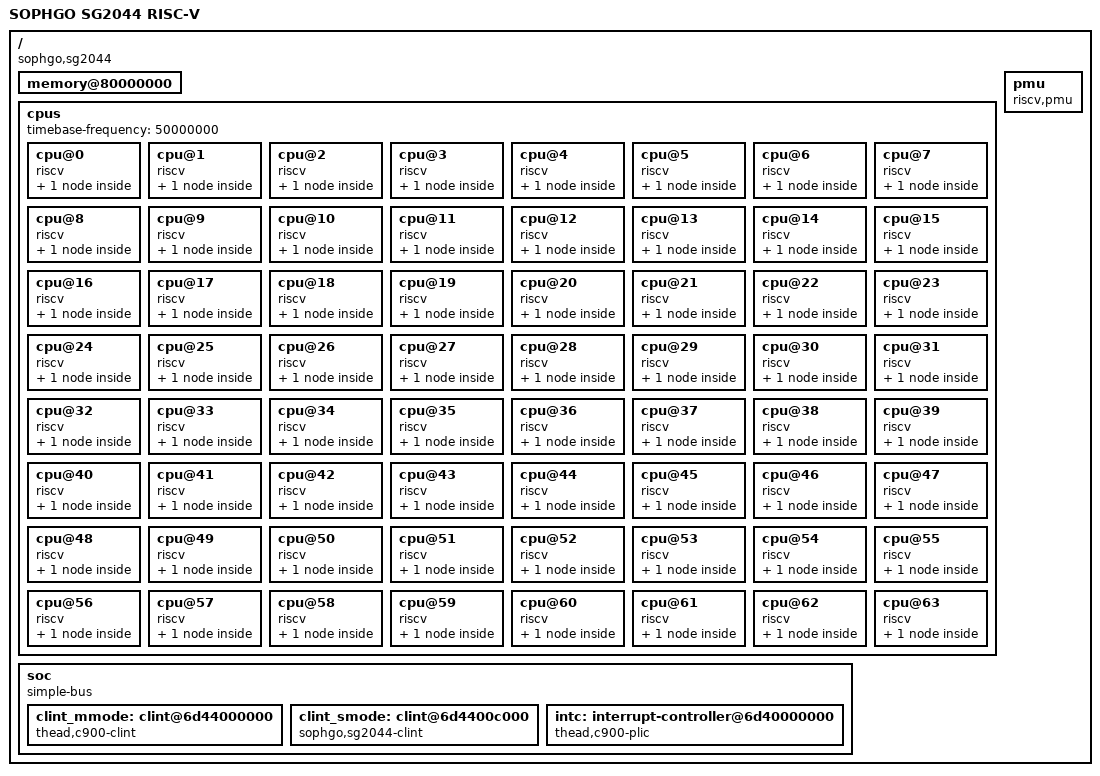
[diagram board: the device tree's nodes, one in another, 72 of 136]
// SPDX-License-Identifier: (GPL-2.0 OR MIT)
/*
 * Copyright (C) 2022 Sophgo Technology Inc. All rights reserved.
 */

/ {
	model = "SOPHGO SG2044 RISC-V";
	compatible = "sophgo,sg2044";
	#address-cells = <2>;
	#size-cells = <2>;
	dma-noncoherent;

	memory@80000000 {
		device_type = "memory";
		reg = <0x00000000 0x80000000 0x00000010 0x00000000>;
	};

	cpus {
		#address-cells = <1>;
		#size-cells = <0>;
		timebase-frequency = <50000000>;
		cpu@0 {
			device_type = "cpu";
			reg = <0>;
			status = "okay";
			compatible = "riscv";
			riscv,isa = "rv64imafdcv_zicbom_zicbop_zicboz_zicond1p0_zihintntl0p2_zihintpause_zawrs_zfa0p1_zfbfmin0p8_zfh_zca_zcb_zcd_zba_zbb_zbc_zbs_zvfbfmin0p8_zvfbfwma0p8_zvfh0p1_sscofpmf_sstc_svinval_svnapot_svpbmt";
			riscv,cbom-block-size = <64>;
			riscv,cboz-block-size = <64>;
			mmu-type = "riscv,sv48";
			cpu0_intc: interrupt-controller {
				#interrupt-cells = <1>;
				compatible = "riscv,cpu-intc";
				interrupt-controller;
			};
		};
		cpu@1 {
			device_type = "cpu";
			reg = <1>;
			status = "okay";
			compatible = "riscv";
			riscv,isa = "rv64imafdcv_zicbom_zicbop_zicboz_zicond1p0_zihintntl0p2_zihintpause_zawrs_zfa0p1_zfbfmin0p8_zfh_zca_zcb_zcd_zba_zbb_zbc_zbs_zvfbfmin0p8_zvfbfwma0p8_zvfh0p1_sscofpmf_sstc_svinval_svnapot_svpbmt";
			riscv,cbom-block-size = <64>;
			riscv,cboz-block-size = <64>;
			mmu-type = "riscv,sv48";
			cpu1_intc: interrupt-controller {
				#interrupt-cells = <1>;
				compatible = "riscv,cpu-intc";
				interrupt-controller;
			};
		};
		cpu@2 {
			device_type = "cpu";
			reg = <2>;
			status = "okay";
			compatible = "riscv";
			riscv,isa = "rv64imafdcv_zicbom_zicbop_zicboz_zicond1p0_zihintntl0p2_zihintpause_zawrs_zfa0p1_zfbfmin0p8_zfh_zca_zcb_zcd_zba_zbb_zbc_zbs_zvfbfmin0p8_zvfbfwma0p8_zvfh0p1_sscofpmf_sstc_svinval_svnapot_svpbmt";
			riscv,cbom-block-size = <64>;
			riscv,cboz-block-size = <64>;
			mmu-type = "riscv,sv48";
			cpu2_intc: interrupt-controller {
				#interrupt-cells = <1>;
				compatible = "riscv,cpu-intc";
				interrupt-controller;
			};
		};
		cpu@3 {
			device_type = "cpu";
			reg = <3>;
			status = "okay";
			compatible = "riscv";
			riscv,isa = "rv64imafdcv_zicbom_zicbop_zicboz_zicond1p0_zihintntl0p2_zihintpause_zawrs_zfa0p1_zfbfmin0p8_zfh_zca_zcb_zcd_zba_zbb_zbc_zbs_zvfbfmin0p8_zvfbfwma0p8_zvfh0p1_sscofpmf_sstc_svinval_svnapot_svpbmt";
			riscv,cbom-block-size = <64>;
			riscv,cboz-block-size = <64>;
			mmu-type = "riscv,sv48";
			cpu3_intc: interrupt-controller {
				#interrupt-cells = <1>;
				compatible = "riscv,cpu-intc";
				interrupt-controller;
			};
		};
		cpu@4 {
			device_type = "cpu";
			reg = <4>;
			status = "okay";
			compatible = "riscv";
			riscv,isa = "rv64imafdcv_zicbom_zicbop_zicboz_zicond1p0_zihintntl0p2_zihintpause_zawrs_zfa0p1_zfbfmin0p8_zfh_zca_zcb_zcd_zba_zbb_zbc_zbs_zvfbfmin0p8_zvfbfwma0p8_zvfh0p1_sscofpmf_sstc_svinval_svnapot_svpbmt";
			riscv,cbom-block-size = <64>;
			riscv,cboz-block-size = <64>;
			mmu-type = "riscv,sv48";
			cpu4_intc: interrupt-controller {
				#interrupt-cells = <1>;
				compatible = "riscv,cpu-intc";
				interrupt-controller;
			};
		};
		cpu@5 {
			device_type = "cpu";
			reg = <5>;
			status = "okay";
			compatible = "riscv";
			riscv,isa = "rv64imafdcv_zicbom_zicbop_zicboz_zicond1p0_zihintntl0p2_zihintpause_zawrs_zfa0p1_zfbfmin0p8_zfh_zca_zcb_zcd_zba_zbb_zbc_zbs_zvfbfmin0p8_zvfbfwma0p8_zvfh0p1_sscofpmf_sstc_svinval_svnapot_svpbmt";
			riscv,cbom-block-size = <64>;
			riscv,cboz-block-size = <64>;
			mmu-type = "riscv,sv48";
			cpu5_intc: interrupt-controller {
				#interrupt-cells = <1>;
				compatible = "riscv,cpu-intc";
				interrupt-controller;
			};
		};
		cpu@6 {
			device_type = "cpu";
			reg = <6>;
			status = "okay";
			compatible = "riscv";
			riscv,isa = "rv64imafdcv_zicbom_zicbop_zicboz_zicond1p0_zihintntl0p2_zihintpause_zawrs_zfa0p1_zfbfmin0p8_zfh_zca_zcb_zcd_zba_zbb_zbc_zbs_zvfbfmin0p8_zvfbfwma0p8_zvfh0p1_sscofpmf_sstc_svinval_svnapot_svpbmt";
			riscv,cbom-block-size = <64>;
			riscv,cboz-block-size = <64>;
			mmu-type = "riscv,sv48";
			cpu6_intc: interrupt-controller {
				#interrupt-cells = <1>;
				compatible = "riscv,cpu-intc";
				interrupt-controller;
			};
		};
		cpu@7 {
			device_type = "cpu";
			reg = <7>;
			status = "okay";
			compatible = "riscv";
			riscv,isa = "rv64imafdcv_zicbom_zicbop_zicboz_zicond1p0_zihintntl0p2_zihintpause_zawrs_zfa0p1_zfbfmin0p8_zfh_zca_zcb_zcd_zba_zbb_zbc_zbs_zvfbfmin0p8_zvfbfwma0p8_zvfh0p1_sscofpmf_sstc_svinval_svnapot_svpbmt";
			riscv,cbom-block-size = <64>;
			riscv,cboz-block-size = <64>;
			mmu-type = "riscv,sv48";
			cpu7_intc: interrupt-controller {
				#interrupt-cells = <1>;
				compatible = "riscv,cpu-intc";
				interrupt-controller;
			};
		};
		cpu@8 {
			device_type = "cpu";
			reg = <8>;
			status = "okay";
			compatible = "riscv";
			riscv,isa = "rv64imafdcv_zicbom_zicbop_zicboz_zicond1p0_zihintntl0p2_zihintpause_zawrs_zfa0p1_zfbfmin0p8_zfh_zca_zcb_zcd_zba_zbb_zbc_zbs_zvfbfmin0p8_zvfbfwma0p8_zvfh0p1_sscofpmf_sstc_svinval_svnapot_svpbmt";
			riscv,cbom-block-size = <64>;
			riscv,cboz-block-size = <64>;
			mmu-type = "riscv,sv48";
			cpu8_intc: interrupt-controller {
				#interrupt-cells = <1>;
				compatible = "riscv,cpu-intc";
				interrupt-controller;
			};
		};
		cpu@9 {
			device_type = "cpu";
			reg = <9>;
			status = "okay";
			compatible = "riscv";
			riscv,isa = "rv64imafdcv_zicbom_zicbop_zicboz_zicond1p0_zihintntl0p2_zihintpause_zawrs_zfa0p1_zfbfmin0p8_zfh_zca_zcb_zcd_zba_zbb_zbc_zbs_zvfbfmin0p8_zvfbfwma0p8_zvfh0p1_sscofpmf_sstc_svinval_svnapot_svpbmt";
			riscv,cbom-block-size = <64>;
			riscv,cboz-block-size = <64>;
			mmu-type = "riscv,sv48";
			cpu9_intc: interrupt-controller {
				#interrupt-cells = <1>;
				compatible = "riscv,cpu-intc";
				interrupt-controller;
			};
		};
		cpu@10 {
			device_type = "cpu";
			reg = <10>;
			status = "okay";
			compatible = "riscv";
			riscv,isa = "rv64imafdcv_zicbom_zicbop_zicboz_zicond1p0_zihintntl0p2_zihintpause_zawrs_zfa0p1_zfbfmin0p8_zfh_zca_zcb_zcd_zba_zbb_zbc_zbs_zvfbfmin0p8_zvfbfwma0p8_zvfh0p1_sscofpmf_sstc_svinval_svnapot_svpbmt";
			riscv,cbom-block-size = <64>;
			riscv,cboz-block-size = <64>;
			mmu-type = "riscv,sv48";
			cpu10_intc: interrupt-controller {
				#interrupt-cells = <1>;
				compatible = "riscv,cpu-intc";
				interrupt-controller;
			};
		};
		cpu@11 {
			device_type = "cpu";
			reg = <11>;
			status = "okay";
			compatible = "riscv";
			riscv,isa = "rv64imafdcv_zicbom_zicbop_zicboz_zicond1p0_zihintntl0p2_zihintpause_zawrs_zfa0p1_zfbfmin0p8_zfh_zca_zcb_zcd_zba_zbb_zbc_zbs_zvfbfmin0p8_zvfbfwma0p8_zvfh0p1_sscofpmf_sstc_svinval_svnapot_svpbmt";
			riscv,cbom-block-size = <64>;
			riscv,cboz-block-size = <64>;
			mmu-type = "riscv,sv48";
			cpu11_intc: interrupt-controller {
				#interrupt-cells = <1>;
				compatible = "riscv,cpu-intc";
				interrupt-controller;
			};
		};
		cpu@12 {
			device_type = "cpu";
			reg = <12>;
			status = "okay";
			compatible = "riscv";
			riscv,isa = "rv64imafdcv_zicbom_zicbop_zicboz_zicond1p0_zihintntl0p2_zihintpause_zawrs_zfa0p1_zfbfmin0p8_zfh_zca_zcb_zcd_zba_zbb_zbc_zbs_zvfbfmin0p8_zvfbfwma0p8_zvfh0p1_sscofpmf_sstc_svinval_svnapot_svpbmt";
			riscv,cbom-block-size = <64>;
			riscv,cboz-block-size = <64>;
			mmu-type = "riscv,sv48";
			cpu12_intc: interrupt-controller {
				#interrupt-cells = <1>;
				compatible = "riscv,cpu-intc";
				interrupt-controller;
			};
		};
		cpu@13 {
			device_type = "cpu";
			reg = <13>;
			status = "okay";
			compatible = "riscv";
			riscv,isa = "rv64imafdcv_zicbom_zicbop_zicboz_zicond1p0_zihintntl0p2_zihintpause_zawrs_zfa0p1_zfbfmin0p8_zfh_zca_zcb_zcd_zba_zbb_zbc_zbs_zvfbfmin0p8_zvfbfwma0p8_zvfh0p1_sscofpmf_sstc_svinval_svnapot_svpbmt";
			riscv,cbom-block-size = <64>;
			riscv,cboz-block-size = <64>;
			mmu-type = "riscv,sv48";
			cpu13_intc: interrupt-controller {
				#interrupt-cells = <1>;
				compatible = "riscv,cpu-intc";
				interrupt-controller;
			};
		};
		cpu@14 {
			device_type = "cpu";
			reg = <14>;
			status = "okay";
			compatible = "riscv";
			riscv,isa = "rv64imafdcv_zicbom_zicbop_zicboz_zicond1p0_zihintntl0p2_zihintpause_zawrs_zfa0p1_zfbfmin0p8_zfh_zca_zcb_zcd_zba_zbb_zbc_zbs_zvfbfmin0p8_zvfbfwma0p8_zvfh0p1_sscofpmf_sstc_svinval_svnapot_svpbmt";
			riscv,cbom-block-size = <64>;
			riscv,cboz-block-size = <64>;
			mmu-type = "riscv,sv48";
			cpu14_intc: interrupt-controller {
				#interrupt-cells = <1>;
				compatible = "riscv,cpu-intc";
				interrupt-controller;
			};
		};
		cpu@15 {
			device_type = "cpu";
			reg = <15>;
			status = "okay";
			compatible = "riscv";
			riscv,isa = "rv64imafdcv_zicbom_zicbop_zicboz_zicond1p0_zihintntl0p2_zihintpause_zawrs_zfa0p1_zfbfmin0p8_zfh_zca_zcb_zcd_zba_zbb_zbc_zbs_zvfbfmin0p8_zvfbfwma0p8_zvfh0p1_sscofpmf_sstc_svinval_svnapot_svpbmt";
			riscv,cbom-block-size = <64>;
			riscv,cboz-block-size = <64>;
			mmu-type = "riscv,sv48";
			cpu15_intc: interrupt-controller {
				#interrupt-cells = <1>;
				compatible = "riscv,cpu-intc";
				interrupt-controller;
			};
		};
		cpu@16 {
			device_type = "cpu";
			reg = <16>;
			status = "okay";
			compatible = "riscv";
			riscv,isa = "rv64imafdcv_zicbom_zicbop_zicboz_zicond1p0_zihintntl0p2_zihintpause_zawrs_zfa0p1_zfbfmin0p8_zfh_zca_zcb_zcd_zba_zbb_zbc_zbs_zvfbfmin0p8_zvfbfwma0p8_zvfh0p1_sscofpmf_sstc_svinval_svnapot_svpbmt";
			riscv,cbom-block-size = <64>;
			riscv,cboz-block-size = <64>;
			mmu-type = "riscv,sv48";
			cpu16_intc: interrupt-controller {
				#interrupt-cells = <1>;
				compatible = "riscv,cpu-intc";
				interrupt-controller;
			};
		};
		cpu@17 {
			device_type = "cpu";
			reg = <17>;
			status = "okay";
			compatible = "riscv";
			riscv,isa = "rv64imafdcv_zicbom_zicbop_zicboz_zicond1p0_zihintntl0p2_zihintpause_zawrs_zfa0p1_zfbfmin0p8_zfh_zca_zcb_zcd_zba_zbb_zbc_zbs_zvfbfmin0p8_zvfbfwma0p8_zvfh0p1_sscofpmf_sstc_svinval_svnapot_svpbmt";
			riscv,cbom-block-size = <64>;
			riscv,cboz-block-size = <64>;
			mmu-type = "riscv,sv48";
			cpu17_intc: interrupt-controller {
				#interrupt-cells = <1>;
				compatible = "riscv,cpu-intc";
				interrupt-controller;
			};
		};
		cpu@18 {
			device_type = "cpu";
			reg = <18>;
			status = "okay";
			compatible = "riscv";
			riscv,isa = "rv64imafdcv_zicbom_zicbop_zicboz_zicond1p0_zihintntl0p2_zihintpause_zawrs_zfa0p1_zfbfmin0p8_zfh_zca_zcb_zcd_zba_zbb_zbc_zbs_zvfbfmin0p8_zvfbfwma0p8_zvfh0p1_sscofpmf_sstc_svinval_svnapot_svpbmt";
			riscv,cbom-block-size = <64>;
			riscv,cboz-block-size = <64>;
			mmu-type = "riscv,sv48";
			cpu18_intc: interrupt-controller {
				#interrupt-cells = <1>;
				compatible = "riscv,cpu-intc";
				interrupt-controller;
			};
		};
		cpu@19 {
			device_type = "cpu";
			reg = <19>;
			status = "okay";
			compatible = "riscv";
			riscv,isa = "rv64imafdcv_zicbom_zicbop_zicboz_zicond1p0_zihintntl0p2_zihintpause_zawrs_zfa0p1_zfbfmin0p8_zfh_zca_zcb_zcd_zba_zbb_zbc_zbs_zvfbfmin0p8_zvfbfwma0p8_zvfh0p1_sscofpmf_sstc_svinval_svnapot_svpbmt";
			riscv,cbom-block-size = <64>;
			riscv,cboz-block-size = <64>;
			mmu-type = "riscv,sv48";
			cpu19_intc: interrupt-controller {
				#interrupt-cells = <1>;
				compatible = "riscv,cpu-intc";
				interrupt-controller;
			};
		};
		cpu@20 {
			device_type = "cpu";
			reg = <20>;
			status = "okay";
			compatible = "riscv";
			riscv,isa = "rv64imafdcv_zicbom_zicbop_zicboz_zicond1p0_zihintntl0p2_zihintpause_zawrs_zfa0p1_zfbfmin0p8_zfh_zca_zcb_zcd_zba_zbb_zbc_zbs_zvfbfmin0p8_zvfbfwma0p8_zvfh0p1_sscofpmf_sstc_svinval_svnapot_svpbmt";
			riscv,cbom-block-size = <64>;
			riscv,cboz-block-size = <64>;
			mmu-type = "riscv,sv48";
			cpu20_intc: interrupt-controller {
				#interrupt-cells = <1>;
				compatible = "riscv,cpu-intc";
				interrupt-controller;
			};
		};
		cpu@21 {
			device_type = "cpu";
			reg = <21>;
			status = "okay";
			compatible = "riscv";
			riscv,isa = "rv64imafdcv_zicbom_zicbop_zicboz_zicond1p0_zihintntl0p2_zihintpause_zawrs_zfa0p1_zfbfmin0p8_zfh_zca_zcb_zcd_zba_zbb_zbc_zbs_zvfbfmin0p8_zvfbfwma0p8_zvfh0p1_sscofpmf_sstc_svinval_svnapot_svpbmt";
			riscv,cbom-block-size = <64>;
			riscv,cboz-block-size = <64>;
			mmu-type = "riscv,sv48";
			cpu21_intc: interrupt-controller {
				#interrupt-cells = <1>;
				compatible = "riscv,cpu-intc";
				interrupt-controller;
			};
		};
		cpu@22 {
			device_type = "cpu";
			reg = <22>;
			status = "okay";
			compatible = "riscv";
			riscv,isa = "rv64imafdcv_zicbom_zicbop_zicboz_zicond1p0_zihintntl0p2_zihintpause_zawrs_zfa0p1_zfbfmin0p8_zfh_zca_zcb_zcd_zba_zbb_zbc_zbs_zvfbfmin0p8_zvfbfwma0p8_zvfh0p1_sscofpmf_sstc_svinval_svnapot_svpbmt";
			riscv,cbom-block-size = <64>;
			riscv,cboz-block-size = <64>;
			mmu-type = "riscv,sv48";
			cpu22_intc: interrupt-controller {
				#interrupt-cells = <1>;
				compatible = "riscv,cpu-intc";
				interrupt-controller;
			};
		};
		cpu@23 {
			device_type = "cpu";
			reg = <23>;
			status = "okay";
			compatible = "riscv";
			riscv,isa = "rv64imafdcv_zicbom_zicbop_zicboz_zicond1p0_zihintntl0p2_zihintpause_zawrs_zfa0p1_zfbfmin0p8_zfh_zca_zcb_zcd_zba_zbb_zbc_zbs_zvfbfmin0p8_zvfbfwma0p8_zvfh0p1_sscofpmf_sstc_svinval_svnapot_svpbmt";
			riscv,cbom-block-size = <64>;
			riscv,cboz-block-size = <64>;
			mmu-type = "riscv,sv48";
			cpu23_intc: interrupt-controller {
				#interrupt-cells = <1>;
				compatible = "riscv,cpu-intc";
				interrupt-controller;
			};
		};
		cpu@24 {
			device_type = "cpu";
			reg = <24>;
			status = "okay";
			compatible = "riscv";
			riscv,isa = "rv64imafdcv_zicbom_zicbop_zicboz_zicond1p0_zihintntl0p2_zihintpause_zawrs_zfa0p1_zfbfmin0p8_zfh_zca_zcb_zcd_zba_zbb_zbc_zbs_zvfbfmin0p8_zvfbfwma0p8_zvfh0p1_sscofpmf_sstc_svinval_svnapot_svpbmt";
			riscv,cbom-block-size = <64>;
			riscv,cboz-block-size = <64>;
			mmu-type = "riscv,sv48";
			cpu24_intc: interrupt-controller {
				#interrupt-cells = <1>;
				compatible = "riscv,cpu-intc";
				interrupt-controller;
			};
		};
		cpu@25 {
			device_type = "cpu";
			reg = <25>;
			status = "okay";
			compatible = "riscv";
			riscv,isa = "rv64imafdcv_zicbom_zicbop_zicboz_zicond1p0_zihintntl0p2_zihintpause_zawrs_zfa0p1_zfbfmin0p8_zfh_zca_zcb_zcd_zba_zbb_zbc_zbs_zvfbfmin0p8_zvfbfwma0p8_zvfh0p1_sscofpmf_sstc_svinval_svnapot_svpbmt";
			riscv,cbom-block-size = <64>;
			riscv,cboz-block-size = <64>;
			mmu-type = "riscv,sv48";
			cpu25_intc: interrupt-controller {
				#interrupt-cells = <1>;
				compatible = "riscv,cpu-intc";
				interrupt-controller;
			};
		};
		cpu@26 {
			device_type = "cpu";
			reg = <26>;
			status = "okay";
			compatible = "riscv";
			riscv,isa = "rv64imafdcv_zicbom_zicbop_zicboz_zicond1p0_zihintntl0p2_zihintpause_zawrs_zfa0p1_zfbfmin0p8_zfh_zca_zcb_zcd_zba_zbb_zbc_zbs_zvfbfmin0p8_zvfbfwma0p8_zvfh0p1_sscofpmf_sstc_svinval_svnapot_svpbmt";
			riscv,cbom-block-size = <64>;
			riscv,cboz-block-size = <64>;
			mmu-type = "riscv,sv48";
			cpu26_intc: interrupt-controller {
				#interrupt-cells = <1>;
				compatible = "riscv,cpu-intc";
				interrupt-controller;
			};
		};
		cpu@27 {
			device_type = "cpu";
			reg = <27>;
			status = "okay";
			compatible = "riscv";
			riscv,isa = "rv64imafdcv_zicbom_zicbop_zicboz_zicond1p0_zihintntl0p2_zihintpause_zawrs_zfa0p1_zfbfmin0p8_zfh_zca_zcb_zcd_zba_zbb_zbc_zbs_zvfbfmin0p8_zvfbfwma0p8_zvfh0p1_sscofpmf_sstc_svinval_svnapot_svpbmt";
			riscv,cbom-block-size = <64>;
			riscv,cboz-block-size = <64>;
			mmu-type = "riscv,sv48";
			cpu27_intc: interrupt-controller {
				#interrupt-cells = <1>;
				compatible = "riscv,cpu-intc";
				interrupt-controller;
			};
		};
		cpu@28 {
			device_type = "cpu";
			reg = <28>;
			status = "okay";
			compatible = "riscv";
			riscv,isa = "rv64imafdcv_zicbom_zicbop_zicboz_zicond1p0_zihintntl0p2_zihintpause_zawrs_zfa0p1_zfbfmin0p8_zfh_zca_zcb_zcd_zba_zbb_zbc_zbs_zvfbfmin0p8_zvfbfwma0p8_zvfh0p1_sscofpmf_sstc_svinval_svnapot_svpbmt";
			riscv,cbom-block-size = <64>;
			riscv,cboz-block-size = <64>;
			mmu-type = "riscv,sv48";
			cpu28_intc: interrupt-controller {
				#interrupt-cells = <1>;
				compatible = "riscv,cpu-intc";
				interrupt-controller;
			};
		};
		cpu@29 {
			device_type = "cpu";
			reg = <29>;
			status = "okay";
			compatible = "riscv";
			riscv,isa = "rv64imafdcv_zicbom_zicbop_zicboz_zicond1p0_zihintntl0p2_zihintpause_zawrs_zfa0p1_zfbfmin0p8_zfh_zca_zcb_zcd_zba_zbb_zbc_zbs_zvfbfmin0p8_zvfbfwma0p8_zvfh0p1_sscofpmf_sstc_svinval_svnapot_svpbmt";
			riscv,cbom-block-size = <64>;
			riscv,cboz-block-size = <64>;
			mmu-type = "riscv,sv48";
			cpu29_intc: interrupt-controller {
				#interrupt-cells = <1>;
				compatible = "riscv,cpu-intc";
				interrupt-controller;
			};
		};
		cpu@30 {
			device_type = "cpu";
			reg = <30>;
			status = "okay";
			compatible = "riscv";
			riscv,isa = "rv64imafdcv_zicbom_zicbop_zicboz_zicond1p0_zihintntl0p2_zihintpause_zawrs_zfa0p1_zfbfmin0p8_zfh_zca_zcb_zcd_zba_zbb_zbc_zbs_zvfbfmin0p8_zvfbfwma0p8_zvfh0p1_sscofpmf_sstc_svinval_svnapot_svpbmt";
			riscv,cbom-block-size = <64>;
			riscv,cboz-block-size = <64>;
			mmu-type = "riscv,sv48";
			cpu30_intc: interrupt-controller {
				#interrupt-cells = <1>;
				compatible = "riscv,cpu-intc";
				interrupt-controller;
			};
		};
		cpu@31 {
			device_type = "cpu";
			reg = <31>;
			status = "okay";
			compatible = "riscv";
			riscv,isa = "rv64imafdcv_zicbom_zicbop_zicboz_zicond1p0_zihintntl0p2_zihintpause_zawrs_zfa0p1_zfbfmin0p8_zfh_zca_zcb_zcd_zba_zbb_zbc_zbs_zvfbfmin0p8_zvfbfwma0p8_zvfh0p1_sscofpmf_sstc_svinval_svnapot_svpbmt";
			riscv,cbom-block-size = <64>;
			riscv,cboz-block-size = <64>;
			mmu-type = "riscv,sv48";
			cpu31_intc: interrupt-controller {
				#interrupt-cells = <1>;
				compatible = "riscv,cpu-intc";
				interrupt-controller;
			};
		};
		cpu@32 {
			device_type = "cpu";
			reg = <32>;
			status = "okay";
			compatible = "riscv";
			riscv,isa = "rv64imafdcv_zicbom_zicbop_zicboz_zicond1p0_zihintntl0p2_zihintpause_zawrs_zfa0p1_zfbfmin0p8_zfh_zca_zcb_zcd_zba_zbb_zbc_zbs_zvfbfmin0p8_zvfbfwma0p8_zvfh0p1_sscofpmf_sstc_svinval_svnapot_svpbmt";
			riscv,cbom-block-size = <64>;
			riscv,cboz-block-size = <64>;
			mmu-type = "riscv,sv48";
			cpu32_intc: interrupt-controller {
				#interrupt-cells = <1>;
				compatible = "riscv,cpu-intc";
				interrupt-controller;
			};
		};
		cpu@33 {
			device_type = "cpu";
			reg = <33>;
			status = "okay";
			compatible = "riscv";
			riscv,isa = "rv64imafdcv_zicbom_zicbop_zicboz_zicond1p0_zihintntl0p2_zihintpause_zawrs_zfa0p1_zfbfmin0p8_zfh_zca_zcb_zcd_zba_zbb_zbc_zbs_zvfbfmin0p8_zvfbfwma0p8_zvfh0p1_sscofpmf_sstc_svinval_svnapot_svpbmt";
			riscv,cbom-block-size = <64>;
			riscv,cboz-block-size = <64>;
			mmu-type = "riscv,sv48";
			cpu33_intc: interrupt-controller {
				#interrupt-cells = <1>;
				compatible = "riscv,cpu-intc";
				interrupt-controller;
			};
		};
		cpu@34 {
			device_type = "cpu";
			reg = <34>;
			status = "okay";
			compatible = "riscv";
			riscv,isa = "rv64imafdcv_zicbom_zicbop_zicboz_zicond1p0_zihintntl0p2_zihintpause_zawrs_zfa0p1_zfbfmin0p8_zfh_zca_zcb_zcd_zba_zbb_zbc_zbs_zvfbfmin0p8_zvfbfwma0p8_zvfh0p1_sscofpmf_sstc_svinval_svnapot_svpbmt";
			riscv,cbom-block-size = <64>;
			riscv,cboz-block-size = <64>;
			mmu-type = "riscv,sv48";
			cpu34_intc: interrupt-controller {
				#interrupt-cells = <1>;
				compatible = "riscv,cpu-intc";
				interrupt-controller;
			};
		};
		cpu@35 {
			device_type = "cpu";
			reg = <35>;
			status = "okay";
			compatible = "riscv";
			riscv,isa = "rv64imafdcv_zicbom_zicbop_zicboz_zicond1p0_zihintntl0p2_zihintpause_zawrs_zfa0p1_zfbfmin0p8_zfh_zca_zcb_zcd_zba_zbb_zbc_zbs_zvfbfmin0p8_zvfbfwma0p8_zvfh0p1_sscofpmf_sstc_svinval_svnapot_svpbmt";
			riscv,cbom-block-size = <64>;
			riscv,cboz-block-size = <64>;
			mmu-type = "riscv,sv48";
			cpu35_intc: interrupt-controller {
				#interrupt-cells = <1>;
				compatible = "riscv,cpu-intc";
				interrupt-controller;
			};
		};
		cpu@36 {
			device_type = "cpu";
			reg = <36>;
			status = "okay";
			compatible = "riscv";
			riscv,isa = "rv64imafdcv_zicbom_zicbop_zicboz_zicond1p0_zihintntl0p2_zihintpause_zawrs_zfa0p1_zfbfmin0p8_zfh_zca_zcb_zcd_zba_zbb_zbc_zbs_zvfbfmin0p8_zvfbfwma0p8_zvfh0p1_sscofpmf_sstc_svinval_svnapot_svpbmt";
			riscv,cbom-block-size = <64>;
			riscv,cboz-block-size = <64>;
			mmu-type = "riscv,sv48";
			cpu36_intc: interrupt-controller {
				#interrupt-cells = <1>;
				compatible = "riscv,cpu-intc";
				interrupt-controller;
			};
		};
		cpu@37 {
			device_type = "cpu";
			reg = <37>;
			status = "okay";
			compatible = "riscv";
			riscv,isa = "rv64imafdcv_zicbom_zicbop_zicboz_zicond1p0_zihintntl0p2_zihintpause_zawrs_zfa0p1_zfbfmin0p8_zfh_zca_zcb_zcd_zba_zbb_zbc_zbs_zvfbfmin0p8_zvfbfwma0p8_zvfh0p1_sscofpmf_sstc_svinval_svnapot_svpbmt";
			riscv,cbom-block-size = <64>;
			riscv,cboz-block-size = <64>;
			mmu-type = "riscv,sv48";
			cpu37_intc: interrupt-controller {
				#interrupt-cells = <1>;
				compatible = "riscv,cpu-intc";
				interrupt-controller;
			};
		};
		cpu@38 {
			device_type = "cpu";
			reg = <38>;
			status = "okay";
			compatible = "riscv";
			riscv,isa = "rv64imafdcv_zicbom_zicbop_zicboz_zicond1p0_zihintntl0p2_zihintpause_zawrs_zfa0p1_zfbfmin0p8_zfh_zca_zcb_zcd_zba_zbb_zbc_zbs_zvfbfmin0p8_zvfbfwma0p8_zvfh0p1_sscofpmf_sstc_svinval_svnapot_svpbmt";
			riscv,cbom-block-size = <64>;
			riscv,cboz-block-size = <64>;
			mmu-type = "riscv,sv48";
			cpu38_intc: interrupt-controller {
				#interrupt-cells = <1>;
				compatible = "riscv,cpu-intc";
				interrupt-controller;
			};
		};
		cpu@39 {
			device_type = "cpu";
			reg = <39>;
			status = "okay";
			compatible = "riscv";
			riscv,isa = "rv64imafdcv_zicbom_zicbop_zicboz_zicond1p0_zihintntl0p2_zihintpause_zawrs_zfa0p1_zfbfmin0p8_zfh_zca_zcb_zcd_zba_zbb_zbc_zbs_zvfbfmin0p8_zvfbfwma0p8_zvfh0p1_sscofpmf_sstc_svinval_svnapot_svpbmt";
			riscv,cbom-block-size = <64>;
			riscv,cboz-block-size = <64>;
			mmu-type = "riscv,sv48";
			cpu39_intc: interrupt-controller {
				#interrupt-cells = <1>;
				compatible = "riscv,cpu-intc";
				interrupt-controller;
			};
		};
		cpu@40 {
			device_type = "cpu";
			reg = <40>;
			status = "okay";
			compatible = "riscv";
			riscv,isa = "rv64imafdcv_zicbom_zicbop_zicboz_zicond1p0_zihintntl0p2_zihintpause_zawrs_zfa0p1_zfbfmin0p8_zfh_zca_zcb_zcd_zba_zbb_zbc_zbs_zvfbfmin0p8_zvfbfwma0p8_zvfh0p1_sscofpmf_sstc_svinval_svnapot_svpbmt";
			riscv,cbom-block-size = <64>;
			riscv,cboz-block-size = <64>;
			mmu-type = "riscv,sv48";
			cpu40_intc: interrupt-controller {
				#interrupt-cells = <1>;
				compatible = "riscv,cpu-intc";
				interrupt-controller;
			};
		};
		cpu@41 {
			device_type = "cpu";
			reg = <41>;
			status = "okay";
			compatible = "riscv";
			riscv,isa = "rv64imafdcv_zicbom_zicbop_zicboz_zicond1p0_zihintntl0p2_zihintpause_zawrs_zfa0p1_zfbfmin0p8_zfh_zca_zcb_zcd_zba_zbb_zbc_zbs_zvfbfmin0p8_zvfbfwma0p8_zvfh0p1_sscofpmf_sstc_svinval_svnapot_svpbmt";
			riscv,cbom-block-size = <64>;
			riscv,cboz-block-size = <64>;
			mmu-type = "riscv,sv48";
			cpu41_intc: interrupt-controller {
				#interrupt-cells = <1>;
				compatible = "riscv,cpu-intc";
				interrupt-controller;
			};
		};
		cpu@42 {
			device_type = "cpu";
			reg = <42>;
			status = "okay";
			compatible = "riscv";
			riscv,isa = "rv64imafdcv_zicbom_zicbop_zicboz_zicond1p0_zihintntl0p2_zihintpause_zawrs_zfa0p1_zfbfmin0p8_zfh_zca_zcb_zcd_zba_zbb_zbc_zbs_zvfbfmin0p8_zvfbfwma0p8_zvfh0p1_sscofpmf_sstc_svinval_svnapot_svpbmt";
			riscv,cbom-block-size = <64>;
			riscv,cboz-block-size = <64>;
			mmu-type = "riscv,sv48";
			cpu42_intc: interrupt-controller {
				#interrupt-cells = <1>;
				compatible = "riscv,cpu-intc";
				interrupt-controller;
			};
		};
		cpu@43 {
			device_type = "cpu";
			reg = <43>;
			status = "okay";
			compatible = "riscv";
			riscv,isa = "rv64imafdcv_zicbom_zicbop_zicboz_zicond1p0_zihintntl0p2_zihintpause_zawrs_zfa0p1_zfbfmin0p8_zfh_zca_zcb_zcd_zba_zbb_zbc_zbs_zvfbfmin0p8_zvfbfwma0p8_zvfh0p1_sscofpmf_sstc_svinval_svnapot_svpbmt";
			riscv,cbom-block-size = <64>;
			riscv,cboz-block-size = <64>;
			mmu-type = "riscv,sv48";
			cpu43_intc: interrupt-controller {
				#interrupt-cells = <1>;
				compatible = "riscv,cpu-intc";
				interrupt-controller;
			};
		};
		cpu@44 {
			device_type = "cpu";
			reg = <44>;
			status = "okay";
			compatible = "riscv";
			riscv,isa = "rv64imafdcv_zicbom_zicbop_zicboz_zicond1p0_zihintntl0p2_zihintpause_zawrs_zfa0p1_zfbfmin0p8_zfh_zca_zcb_zcd_zba_zbb_zbc_zbs_zvfbfmin0p8_zvfbfwma0p8_zvfh0p1_sscofpmf_sstc_svinval_svnapot_svpbmt";
			riscv,cbom-block-size = <64>;
			riscv,cboz-block-size = <64>;
			mmu-type = "riscv,sv48";
			cpu44_intc: interrupt-controller {
				#interrupt-cells = <1>;
				compatible = "riscv,cpu-intc";
				interrupt-controller;
			};
		};
		cpu@45 {
			device_type = "cpu";
			reg = <45>;
			status = "okay";
			compatible = "riscv";
			riscv,isa = "rv64imafdcv_zicbom_zicbop_zicboz_zicond1p0_zihintntl0p2_zihintpause_zawrs_zfa0p1_zfbfmin0p8_zfh_zca_zcb_zcd_zba_zbb_zbc_zbs_zvfbfmin0p8_zvfbfwma0p8_zvfh0p1_sscofpmf_sstc_svinval_svnapot_svpbmt";
			riscv,cbom-block-size = <64>;
			riscv,cboz-block-size = <64>;
			mmu-type = "riscv,sv48";
			cpu45_intc: interrupt-controller {
				#interrupt-cells = <1>;
				compatible = "riscv,cpu-intc";
				interrupt-controller;
			};
		};
		cpu@46 {
			device_type = "cpu";
			reg = <46>;
			status = "okay";
			compatible = "riscv";
			riscv,isa = "rv64imafdcv_zicbom_zicbop_zicboz_zicond1p0_zihintntl0p2_zihintpause_zawrs_zfa0p1_zfbfmin0p8_zfh_zca_zcb_zcd_zba_zbb_zbc_zbs_zvfbfmin0p8_zvfbfwma0p8_zvfh0p1_sscofpmf_sstc_svinval_svnapot_svpbmt";
			riscv,cbom-block-size = <64>;
			riscv,cboz-block-size = <64>;
			mmu-type = "riscv,sv48";
			cpu46_intc: interrupt-controller {
				#interrupt-cells = <1>;
				compatible = "riscv,cpu-intc";
				interrupt-controller;
			};
		};
		cpu@47 {
			device_type = "cpu";
			reg = <47>;
			status = "okay";
			compatible = "riscv";
			riscv,isa = "rv64imafdcv_zicbom_zicbop_zicboz_zicond1p0_zihintntl0p2_zihintpause_zawrs_zfa0p1_zfbfmin0p8_zfh_zca_zcb_zcd_zba_zbb_zbc_zbs_zvfbfmin0p8_zvfbfwma0p8_zvfh0p1_sscofpmf_sstc_svinval_svnapot_svpbmt";
			riscv,cbom-block-size = <64>;
			riscv,cboz-block-size = <64>;
			mmu-type = "riscv,sv48";
			cpu47_intc: interrupt-controller {
				#interrupt-cells = <1>;
				compatible = "riscv,cpu-intc";
				interrupt-controller;
			};
		};
		cpu@48 {
			device_type = "cpu";
			reg = <48>;
			status = "okay";
			compatible = "riscv";
			riscv,isa = "rv64imafdcv_zicbom_zicbop_zicboz_zicond1p0_zihintntl0p2_zihintpause_zawrs_zfa0p1_zfbfmin0p8_zfh_zca_zcb_zcd_zba_zbb_zbc_zbs_zvfbfmin0p8_zvfbfwma0p8_zvfh0p1_sscofpmf_sstc_svinval_svnapot_svpbmt";
			riscv,cbom-block-size = <64>;
			riscv,cboz-block-size = <64>;
			mmu-type = "riscv,sv48";
			cpu48_intc: interrupt-controller {
				#interrupt-cells = <1>;
				compatible = "riscv,cpu-intc";
				interrupt-controller;
			};
		};
		cpu@49 {
			device_type = "cpu";
			reg = <49>;
			status = "okay";
			compatible = "riscv";
			riscv,isa = "rv64imafdcv_zicbom_zicbop_zicboz_zicond1p0_zihintntl0p2_zihintpause_zawrs_zfa0p1_zfbfmin0p8_zfh_zca_zcb_zcd_zba_zbb_zbc_zbs_zvfbfmin0p8_zvfbfwma0p8_zvfh0p1_sscofpmf_sstc_svinval_svnapot_svpbmt";
			riscv,cbom-block-size = <64>;
			riscv,cboz-block-size = <64>;
			mmu-type = "riscv,sv48";
			cpu49_intc: interrupt-controller {
				#interrupt-cells = <1>;
				compatible = "riscv,cpu-intc";
				interrupt-controller;
			};
		};
		cpu@50 {
			device_type = "cpu";
			reg = <50>;
			status = "okay";
			compatible = "riscv";
			riscv,isa = "rv64imafdcv_zicbom_zicbop_zicboz_zicond1p0_zihintntl0p2_zihintpause_zawrs_zfa0p1_zfbfmin0p8_zfh_zca_zcb_zcd_zba_zbb_zbc_zbs_zvfbfmin0p8_zvfbfwma0p8_zvfh0p1_sscofpmf_sstc_svinval_svnapot_svpbmt";
			riscv,cbom-block-size = <64>;
			riscv,cboz-block-size = <64>;
			mmu-type = "riscv,sv48";
			cpu50_intc: interrupt-controller {
				#interrupt-cells = <1>;
				compatible = "riscv,cpu-intc";
				interrupt-controller;
			};
		};
		cpu@51 {
			device_type = "cpu";
			reg = <51>;
			status = "okay";
			compatible = "riscv";
			riscv,isa = "rv64imafdcv_zicbom_zicbop_zicboz_zicond1p0_zihintntl0p2_zihintpause_zawrs_zfa0p1_zfbfmin0p8_zfh_zca_zcb_zcd_zba_zbb_zbc_zbs_zvfbfmin0p8_zvfbfwma0p8_zvfh0p1_sscofpmf_sstc_svinval_svnapot_svpbmt";
			riscv,cbom-block-size = <64>;
			riscv,cboz-block-size = <64>;
			mmu-type = "riscv,sv48";
			cpu51_intc: interrupt-controller {
				#interrupt-cells = <1>;
				compatible = "riscv,cpu-intc";
				interrupt-controller;
			};
		};
		cpu@52 {
			device_type = "cpu";
			reg = <52>;
			status = "okay";
			compatible = "riscv";
			riscv,isa = "rv64imafdcv_zicbom_zicbop_zicboz_zicond1p0_zihintntl0p2_zihintpause_zawrs_zfa0p1_zfbfmin0p8_zfh_zca_zcb_zcd_zba_zbb_zbc_zbs_zvfbfmin0p8_zvfbfwma0p8_zvfh0p1_sscofpmf_sstc_svinval_svnapot_svpbmt";
			riscv,cbom-block-size = <64>;
			riscv,cboz-block-size = <64>;
			mmu-type = "riscv,sv48";
			cpu52_intc: interrupt-controller {
				#interrupt-cells = <1>;
				compatible = "riscv,cpu-intc";
				interrupt-controller;
			};
		};
		cpu@53 {
			device_type = "cpu";
			reg = <53>;
			status = "okay";
			compatible = "riscv";
			riscv,isa = "rv64imafdcv_zicbom_zicbop_zicboz_zicond1p0_zihintntl0p2_zihintpause_zawrs_zfa0p1_zfbfmin0p8_zfh_zca_zcb_zcd_zba_zbb_zbc_zbs_zvfbfmin0p8_zvfbfwma0p8_zvfh0p1_sscofpmf_sstc_svinval_svnapot_svpbmt";
			riscv,cbom-block-size = <64>;
			riscv,cboz-block-size = <64>;
			mmu-type = "riscv,sv48";
			cpu53_intc: interrupt-controller {
				#interrupt-cells = <1>;
				compatible = "riscv,cpu-intc";
				interrupt-controller;
			};
		};
		cpu@54 {
			device_type = "cpu";
			reg = <54>;
			status = "okay";
			compatible = "riscv";
			riscv,isa = "rv64imafdcv_zicbom_zicbop_zicboz_zicond1p0_zihintntl0p2_zihintpause_zawrs_zfa0p1_zfbfmin0p8_zfh_zca_zcb_zcd_zba_zbb_zbc_zbs_zvfbfmin0p8_zvfbfwma0p8_zvfh0p1_sscofpmf_sstc_svinval_svnapot_svpbmt";
			riscv,cbom-block-size = <64>;
			riscv,cboz-block-size = <64>;
			mmu-type = "riscv,sv48";
			cpu54_intc: interrupt-controller {
				#interrupt-cells = <1>;
				compatible = "riscv,cpu-intc";
				interrupt-controller;
			};
		};
		cpu@55 {
			device_type = "cpu";
			reg = <55>;
			status = "okay";
			compatible = "riscv";
			riscv,isa = "rv64imafdcv_zicbom_zicbop_zicboz_zicond1p0_zihintntl0p2_zihintpause_zawrs_zfa0p1_zfbfmin0p8_zfh_zca_zcb_zcd_zba_zbb_zbc_zbs_zvfbfmin0p8_zvfbfwma0p8_zvfh0p1_sscofpmf_sstc_svinval_svnapot_svpbmt";
			riscv,cbom-block-size = <64>;
			riscv,cboz-block-size = <64>;
			mmu-type = "riscv,sv48";
			cpu55_intc: interrupt-controller {
				#interrupt-cells = <1>;
				compatible = "riscv,cpu-intc";
				interrupt-controller;
			};
		};
		cpu@56 {
			device_type = "cpu";
			reg = <56>;
			status = "okay";
			compatible = "riscv";
			riscv,isa = "rv64imafdcv_zicbom_zicbop_zicboz_zicond1p0_zihintntl0p2_zihintpause_zawrs_zfa0p1_zfbfmin0p8_zfh_zca_zcb_zcd_zba_zbb_zbc_zbs_zvfbfmin0p8_zvfbfwma0p8_zvfh0p1_sscofpmf_sstc_svinval_svnapot_svpbmt";
			riscv,cbom-block-size = <64>;
			riscv,cboz-block-size = <64>;
			mmu-type = "riscv,sv48";
			cpu56_intc: interrupt-controller {
				#interrupt-cells = <1>;
				compatible = "riscv,cpu-intc";
				interrupt-controller;
			};
		};
		cpu@57 {
			device_type = "cpu";
			reg = <57>;
			status = "okay";
			compatible = "riscv";
			riscv,isa = "rv64imafdcv_zicbom_zicbop_zicboz_zicond1p0_zihintntl0p2_zihintpause_zawrs_zfa0p1_zfbfmin0p8_zfh_zca_zcb_zcd_zba_zbb_zbc_zbs_zvfbfmin0p8_zvfbfwma0p8_zvfh0p1_sscofpmf_sstc_svinval_svnapot_svpbmt";
			riscv,cbom-block-size = <64>;
			riscv,cboz-block-size = <64>;
			mmu-type = "riscv,sv48";
			cpu57_intc: interrupt-controller {
				#interrupt-cells = <1>;
				compatible = "riscv,cpu-intc";
				interrupt-controller;
			};
		};
		cpu@58 {
			device_type = "cpu";
			reg = <58>;
			status = "okay";
			compatible = "riscv";
			riscv,isa = "rv64imafdcv_zicbom_zicbop_zicboz_zicond1p0_zihintntl0p2_zihintpause_zawrs_zfa0p1_zfbfmin0p8_zfh_zca_zcb_zcd_zba_zbb_zbc_zbs_zvfbfmin0p8_zvfbfwma0p8_zvfh0p1_sscofpmf_sstc_svinval_svnapot_svpbmt";
			riscv,cbom-block-size = <64>;
			riscv,cboz-block-size = <64>;
			mmu-type = "riscv,sv48";
			cpu58_intc: interrupt-controller {
				#interrupt-cells = <1>;
				compatible = "riscv,cpu-intc";
				interrupt-controller;
			};
		};
		cpu@59 {
			device_type = "cpu";
			reg = <59>;
			status = "okay";
			compatible = "riscv";
			riscv,isa = "rv64imafdcv_zicbom_zicbop_zicboz_zicond1p0_zihintntl0p2_zihintpause_zawrs_zfa0p1_zfbfmin0p8_zfh_zca_zcb_zcd_zba_zbb_zbc_zbs_zvfbfmin0p8_zvfbfwma0p8_zvfh0p1_sscofpmf_sstc_svinval_svnapot_svpbmt";
			riscv,cbom-block-size = <64>;
			riscv,cboz-block-size = <64>;
			mmu-type = "riscv,sv48";
			cpu59_intc: interrupt-controller {
				#interrupt-cells = <1>;
				compatible = "riscv,cpu-intc";
				interrupt-controller;
			};
		};
		cpu@60 {
			device_type = "cpu";
			reg = <60>;
			status = "okay";
			compatible = "riscv";
			riscv,isa = "rv64imafdcv_zicbom_zicbop_zicboz_zicond1p0_zihintntl0p2_zihintpause_zawrs_zfa0p1_zfbfmin0p8_zfh_zca_zcb_zcd_zba_zbb_zbc_zbs_zvfbfmin0p8_zvfbfwma0p8_zvfh0p1_sscofpmf_sstc_svinval_svnapot_svpbmt";
			riscv,cbom-block-size = <64>;
			riscv,cboz-block-size = <64>;
			mmu-type = "riscv,sv48";
			cpu60_intc: interrupt-controller {
				#interrupt-cells = <1>;
				compatible = "riscv,cpu-intc";
				interrupt-controller;
			};
		};
		cpu@61 {
			device_type = "cpu";
			reg = <61>;
			status = "okay";
			compatible = "riscv";
			riscv,isa = "rv64imafdcv_zicbom_zicbop_zicboz_zicond1p0_zihintntl0p2_zihintpause_zawrs_zfa0p1_zfbfmin0p8_zfh_zca_zcb_zcd_zba_zbb_zbc_zbs_zvfbfmin0p8_zvfbfwma0p8_zvfh0p1_sscofpmf_sstc_svinval_svnapot_svpbmt";
			riscv,cbom-block-size = <64>;
			riscv,cboz-block-size = <64>;
			mmu-type = "riscv,sv48";
			cpu61_intc: interrupt-controller {
				#interrupt-cells = <1>;
				compatible = "riscv,cpu-intc";
				interrupt-controller;
			};
		};
		cpu@62 {
			device_type = "cpu";
			reg = <62>;
			status = "okay";
			compatible = "riscv";
			riscv,isa = "rv64imafdcv_zicbom_zicbop_zicboz_zicond1p0_zihintntl0p2_zihintpause_zawrs_zfa0p1_zfbfmin0p8_zfh_zca_zcb_zcd_zba_zbb_zbc_zbs_zvfbfmin0p8_zvfbfwma0p8_zvfh0p1_sscofpmf_sstc_svinval_svnapot_svpbmt";
			riscv,cbom-block-size = <64>;
			riscv,cboz-block-size = <64>;
			mmu-type = "riscv,sv48";
			cpu62_intc: interrupt-controller {
				#interrupt-cells = <1>;
				compatible = "riscv,cpu-intc";
				interrupt-controller;
			};
		};
		cpu@63 {
			device_type = "cpu";
			reg = <63>;
			status = "okay";
			compatible = "riscv";
			riscv,isa = "rv64imafdcv_zicbom_zicbop_zicboz_zicond1p0_zihintntl0p2_zihintpause_zawrs_zfa0p1_zfbfmin0p8_zfh_zca_zcb_zcd_zba_zbb_zbc_zbs_zvfbfmin0p8_zvfbfwma0p8_zvfh0p1_sscofpmf_sstc_svinval_svnapot_svpbmt";
			riscv,cbom-block-size = <64>;
			riscv,cboz-block-size = <64>;
			mmu-type = "riscv,sv48";
			cpu63_intc: interrupt-controller {
				#interrupt-cells = <1>;
				compatible = "riscv,cpu-intc";
				interrupt-controller;
			};
		};
	};

	pmu {
		compatible = "riscv,pmu";
		riscv,event-to-mhpmevent =
			<0x00003 0x00000000 0x00000010>,
			<0x00004 0x00000000 0x00000011>,
			<0x00005 0x00000000 0x00000007>,
			<0x00006 0x00000000 0x00000006>,
			<0x00008 0x00000000 0x00000027>,
			<0x00009 0x00000000 0x00000028>,
			<0x10000 0x00000000 0x0000000c>,
			<0x10001 0x00000000 0x0000000d>,
			<0x10002 0x00000000 0x0000000e>,
			<0x10003 0x00000000 0x0000000f>,
			<0x10008 0x00000000 0x00000001>,
			<0x10009 0x00000000 0x00000002>,
			<0x10010 0x00000000 0x00000010>,
			<0x10011 0x00000000 0x00000011>,
			<0x10012 0x00000000 0x00000012>,
			<0x10013 0x00000000 0x00000013>,
			<0x10019 0x00000000 0x00000004>,
			<0x10021 0x00000000 0x00000003>,
			<0x10030 0x00000000 0x0000001c>,
			<0x10031 0x00000000 0x0000001b>;
		riscv,event-to-mhpmcounters =
			<0x00003 0x00003 0xfffffff8>,
			<0x00004 0x00004 0xfffffff8>,
			<0x00005 0x00005 0xfffffff8>,
			<0x00006 0x00006 0xfffffff8>,
			<0x00007 0x00007 0xfffffff8>,
			<0x00008 0x00008 0xfffffff8>,
			<0x00009 0x00009 0xfffffff8>,
			<0x0000a 0x0000a 0xfffffff8>,
			<0x10000 0x10000 0xfffffff8>,
			<0x10001 0x10001 0xfffffff8>,
			<0x10002 0x10002 0xfffffff8>,
			<0x10003 0x10003 0xfffffff8>,
			<0x10008 0x10008 0xfffffff8>,
			<0x10009 0x10009 0xfffffff8>,
			<0x10010 0x10010 0xfffffff8>,
			<0x10011 0x10011 0xfffffff8>,
			<0x10012 0x10012 0xfffffff8>,
			<0x10013 0x10013 0xfffffff8>,
			<0x10019 0x10019 0xfffffff8>,
			<0x10021 0x10021 0xfffffff8>,
			<0x10030 0x10030 0xfffffff8>,
			<0x10031 0x10031 0xfffffff8>;
		riscv,raw-event-to-mhpmcounters =
			<0x00000000 0x00000001 0xffffffff 0xffffffff 0xfffffff8>,
			<0x00000000 0x00000002 0xffffffff 0xffffffff 0xfffffff8>,
			<0x00000000 0x00000003 0xffffffff 0xffffffff 0xfffffff8>,
			<0x00000000 0x00000004 0xffffffff 0xffffffff 0xfffffff8>,
			<0x00000000 0x00000005 0xffffffff 0xffffffff 0xfffffff8>,
			<0x00000000 0x00000006 0xffffffff 0xffffffff 0xfffffff8>,
			<0x00000000 0x00000007 0xffffffff 0xffffffff 0xfffffff8>,
			<0x00000000 0x00000008 0xffffffff 0xffffffff 0xfffffff8>,
			<0x00000000 0x00000009 0xffffffff 0xffffffff 0xfffffff8>,
			<0x00000000 0x0000000a 0xffffffff 0xffffffff 0xfffffff8>,
			<0x00000000 0x0000000b 0xffffffff 0xffffffff 0xfffffff8>,
			<0x00000000 0x0000000c 0xffffffff 0xffffffff 0xfffffff8>,
			<0x00000000 0x0000000d 0xffffffff 0xffffffff 0xfffffff8>,
			<0x00000000 0x0000000e 0xffffffff 0xffffffff 0xfffffff8>,
			<0x00000000 0x0000000f 0xffffffff 0xffffffff 0xfffffff8>,
			<0x00000000 0x00000010 0xffffffff 0xffffffff 0xfffffff8>,
			<0x00000000 0x00000011 0xffffffff 0xffffffff 0xfffffff8>,
			<0x00000000 0x00000012 0xffffffff 0xffffffff 0xfffffff8>,
			<0x00000000 0x00000013 0xffffffff 0xffffffff 0xfffffff8>,
			<0x00000000 0x00000014 0xffffffff 0xffffffff 0xfffffff8>,
			<0x00000000 0x00000015 0xffffffff 0xffffffff 0xfffffff8>,
			<0x00000000 0x00000016 0xffffffff 0xffffffff 0xfffffff8>,
			<0x00000000 0x00000017 0xffffffff 0xffffffff 0xfffffff8>,
			<0x00000000 0x00000018 0xffffffff 0xffffffff 0xfffffff8>,
			<0x00000000 0x00000019 0xffffffff 0xffffffff 0xfffffff8>,
			<0x00000000 0x0000001a 0xffffffff 0xffffffff 0xfffffff8>,
			<0x00000000 0x0000001b 0xffffffff 0xffffffff 0xfffffff8>,
			<0x00000000 0x0000001c 0xffffffff 0xffffffff 0xfffffff8>,
			<0x00000000 0x0000001d 0xffffffff 0xffffffff 0xfffffff8>,
			<0x00000000 0x0000001e 0xffffffff 0xffffffff 0xfffffff8>,
			<0x00000000 0x0000001f 0xffffffff 0xffffffff 0xfffffff8>,
			<0x00000000 0x00000020 0xffffffff 0xffffffff 0xfffffff8>,
			<0x00000000 0x00000021 0xffffffff 0xffffffff 0xfffffff8>,
			<0x00000000 0x00000022 0xffffffff 0xffffffff 0xfffffff8>,
			<0x00000000 0x00000023 0xffffffff 0xffffffff 0xfffffff8>,
			<0x00000000 0x00000024 0xffffffff 0xffffffff 0xfffffff8>,
			<0x00000000 0x00000025 0xffffffff 0xffffffff 0xfffffff8>,
			<0x00000000 0x00000026 0xffffffff 0xffffffff 0xfffffff8>,
			<0x00000000 0x00000027 0xffffffff 0xffffffff 0xfffffff8>,
			<0x00000000 0x00000028 0xffffffff 0xffffffff 0xfffffff8>,
			<0x00000000 0x00000029 0xffffffff 0xffffffff 0xfffffff8>,
			<0x00000000 0x0000002a 0xffffffff 0xffffffff 0xfffffff8>;
	};

	soc {
		#address-cells = <2>;
		#size-cells = <2>;
		compatible = "simple-bus";
		ranges;

		clint_mmode: clint@6d44000000 {
		         compatible = "thead,c900-clint";
		         reg = <0x0000006d 0x44000000 0x00000000 0x0000c000>;
		         interrupts-extended = <&cpu0_intc  3>, <&cpu0_intc  7>,
		                               <&cpu1_intc  3>, <&cpu1_intc  7>,
		                               <&cpu2_intc  3>, <&cpu2_intc  7>,
		                               <&cpu3_intc  3>, <&cpu3_intc  7>,
		                               <&cpu4_intc  3>, <&cpu4_intc  7>,
		                               <&cpu5_intc  3>, <&cpu5_intc  7>,
		                               <&cpu6_intc  3>, <&cpu6_intc  7>,
		                               <&cpu7_intc  3>, <&cpu7_intc  7>,
		                               <&cpu8_intc  3>, <&cpu8_intc  7>,
		                               <&cpu9_intc  3>, <&cpu9_intc  7>,
		                               <&cpu10_intc 3>, <&cpu10_intc 7>,
		                               <&cpu11_intc 3>, <&cpu11_intc 7>,
		                               <&cpu12_intc 3>, <&cpu12_intc 7>,
		                               <&cpu13_intc 3>, <&cpu13_intc 7>,
		                               <&cpu14_intc 3>, <&cpu14_intc 7>,
		                               <&cpu15_intc 3>, <&cpu15_intc 7>,
		                               <&cpu16_intc 3>, <&cpu16_intc 7>,
		                               <&cpu17_intc 3>, <&cpu17_intc 7>,
		                               <&cpu18_intc 3>, <&cpu18_intc 7>,
		                               <&cpu19_intc 3>, <&cpu19_intc 7>,
		                               <&cpu20_intc 3>, <&cpu20_intc 7>,
		                               <&cpu21_intc 3>, <&cpu21_intc 7>,
		                               <&cpu22_intc 3>, <&cpu22_intc 7>,
		                               <&cpu23_intc 3>, <&cpu23_intc 7>,
		                               <&cpu24_intc 3>, <&cpu24_intc 7>,
		                               <&cpu25_intc 3>, <&cpu25_intc 7>,
		                               <&cpu26_intc 3>, <&cpu26_intc 7>,
		                               <&cpu27_intc 3>, <&cpu27_intc 7>,
		                               <&cpu28_intc 3>, <&cpu28_intc 7>,
		                               <&cpu29_intc 3>, <&cpu29_intc 7>,
		                               <&cpu30_intc 3>, <&cpu30_intc 7>,
		                               <&cpu31_intc 3>, <&cpu31_intc 7>,
		                               <&cpu32_intc 3>, <&cpu32_intc 7>,
		                               <&cpu33_intc 3>, <&cpu33_intc 7>,
		                               <&cpu34_intc 3>, <&cpu34_intc 7>,
		                               <&cpu35_intc 3>, <&cpu35_intc 7>,
		                               <&cpu36_intc 3>, <&cpu36_intc 7>,
		                               <&cpu37_intc 3>, <&cpu37_intc 7>,
		                               <&cpu38_intc 3>, <&cpu38_intc 7>,
		                               <&cpu39_intc 3>, <&cpu39_intc 7>,
		                               <&cpu40_intc 3>, <&cpu40_intc 7>,
		                               <&cpu41_intc 3>, <&cpu41_intc 7>,
		                               <&cpu42_intc 3>, <&cpu42_intc 7>,
		                               <&cpu43_intc 3>, <&cpu43_intc 7>,
		                               <&cpu44_intc 3>, <&cpu44_intc 7>,
		                               <&cpu45_intc 3>, <&cpu45_intc 7>,
		                               <&cpu46_intc 3>, <&cpu46_intc 7>,
		                               <&cpu47_intc 3>, <&cpu47_intc 7>,
		                               <&cpu48_intc 3>, <&cpu48_intc 7>,
		                               <&cpu49_intc 3>, <&cpu49_intc 7>,
		                               <&cpu50_intc 3>, <&cpu50_intc 7>,
		                               <&cpu51_intc 3>, <&cpu51_intc 7>,
		                               <&cpu52_intc 3>, <&cpu52_intc 7>,
		                               <&cpu53_intc 3>, <&cpu53_intc 7>,
		                               <&cpu54_intc 3>, <&cpu54_intc 7>,
		                               <&cpu55_intc 3>, <&cpu55_intc 7>,
		                               <&cpu56_intc 3>, <&cpu56_intc 7>,
		                               <&cpu57_intc 3>, <&cpu57_intc 7>,
		                               <&cpu58_intc 3>, <&cpu58_intc 7>,
		                               <&cpu59_intc 3>, <&cpu59_intc 7>,
		                               <&cpu60_intc 3>, <&cpu60_intc 7>,
		                               <&cpu61_intc 3>, <&cpu61_intc 7>,
		                               <&cpu62_intc 3>, <&cpu62_intc 7>,
		                               <&cpu63_intc 3>, <&cpu63_intc 7>;
		};

		clint_smode: clint@6d4400c000 {
		         compatible = "sophgo,sg2044-clint";
		         reg = <0x0000006d 0x4400c000 0x00000000 0x00004000>;
			 interrupt-controller;
		         interrupts-extended = <&cpu0_intc  1>, <&cpu0_intc  5>,
		                               <&cpu1_intc  1>, <&cpu1_intc  5>,
		                               <&cpu2_intc  1>, <&cpu2_intc  5>,
		                               <&cpu3_intc  1>, <&cpu3_intc  5>,
		                               <&cpu4_intc  1>, <&cpu4_intc  5>,
		                               <&cpu5_intc  1>, <&cpu5_intc  5>,
		                               <&cpu6_intc  1>, <&cpu6_intc  5>,
		                               <&cpu7_intc  1>, <&cpu7_intc  5>,
		                               <&cpu8_intc  1>, <&cpu8_intc  5>,
		                               <&cpu9_intc  1>, <&cpu9_intc  5>,
		                               <&cpu10_intc 1>, <&cpu10_intc 5>,
		                               <&cpu11_intc 1>, <&cpu11_intc 5>,
		                               <&cpu12_intc 1>, <&cpu12_intc 5>,
		                               <&cpu13_intc 1>, <&cpu13_intc 5>,
		                               <&cpu14_intc 1>, <&cpu14_intc 5>,
		                               <&cpu15_intc 1>, <&cpu15_intc 5>,
		                               <&cpu16_intc 1>, <&cpu16_intc 5>,
		                               <&cpu17_intc 1>, <&cpu17_intc 5>,
		                               <&cpu18_intc 1>, <&cpu18_intc 5>,
		                               <&cpu19_intc 1>, <&cpu19_intc 5>,
		                               <&cpu20_intc 1>, <&cpu20_intc 5>,
		                               <&cpu21_intc 1>, <&cpu21_intc 5>,
		                               <&cpu22_intc 1>, <&cpu22_intc 5>,
		                               <&cpu23_intc 1>, <&cpu23_intc 5>,
		                               <&cpu24_intc 1>, <&cpu24_intc 5>,
		                               <&cpu25_intc 1>, <&cpu25_intc 5>,
		                               <&cpu26_intc 1>, <&cpu26_intc 5>,
		                               <&cpu27_intc 1>, <&cpu27_intc 5>,
		                               <&cpu28_intc 1>, <&cpu28_intc 5>,
		                               <&cpu29_intc 1>, <&cpu29_intc 5>,
		                               <&cpu30_intc 1>, <&cpu30_intc 5>,
		                               <&cpu31_intc 1>, <&cpu31_intc 5>,
		                               <&cpu32_intc 1>, <&cpu32_intc 5>,
		                               <&cpu33_intc 1>, <&cpu33_intc 5>,
		                               <&cpu34_intc 1>, <&cpu34_intc 5>,
		                               <&cpu35_intc 1>, <&cpu35_intc 5>,
		                               <&cpu36_intc 1>, <&cpu36_intc 5>,
		                               <&cpu37_intc 1>, <&cpu37_intc 5>,
		                               <&cpu38_intc 1>, <&cpu38_intc 5>,
		                               <&cpu39_intc 1>, <&cpu39_intc 5>,
		                               <&cpu40_intc 1>, <&cpu40_intc 5>,
		                               <&cpu41_intc 1>, <&cpu41_intc 5>,
		                               <&cpu42_intc 1>, <&cpu42_intc 5>,
		                               <&cpu43_intc 1>, <&cpu43_intc 5>,
		                               <&cpu44_intc 1>, <&cpu44_intc 5>,
		                               <&cpu45_intc 1>, <&cpu45_intc 5>,
		                               <&cpu46_intc 1>, <&cpu46_intc 5>,
		                               <&cpu47_intc 1>, <&cpu47_intc 5>,
		                               <&cpu48_intc 1>, <&cpu48_intc 5>,
		                               <&cpu49_intc 1>, <&cpu49_intc 5>,
		                               <&cpu50_intc 1>, <&cpu50_intc 5>,
		                               <&cpu51_intc 1>, <&cpu51_intc 5>,
		                               <&cpu52_intc 1>, <&cpu52_intc 5>,
		                               <&cpu53_intc 1>, <&cpu53_intc 5>,
		                               <&cpu54_intc 1>, <&cpu54_intc 5>,
		                               <&cpu55_intc 1>, <&cpu55_intc 5>,
		                               <&cpu56_intc 1>, <&cpu56_intc 5>,
		                               <&cpu57_intc 1>, <&cpu57_intc 5>,
		                               <&cpu58_intc 1>, <&cpu58_intc 5>,
		                               <&cpu59_intc 1>, <&cpu59_intc 5>,
		                               <&cpu60_intc 1>, <&cpu60_intc 5>,
		                               <&cpu61_intc 1>, <&cpu61_intc 5>,
		                               <&cpu62_intc 1>, <&cpu62_intc 5>,
		                               <&cpu63_intc 1>, <&cpu63_intc 5>;
		};

		intc: interrupt-controller@6d40000000 {
			compatible = "thead,c900-plic";
			#address-cells = <0>;
			#interrupt-cells = <2>;
			reg = <0x0000006d 0x40000000 0x00000000 0x10000000>;
			riscv,ndev = <863>;
			interrupt-controller;
			interrupts-extended = <&cpu0_intc   11>, < &cpu0_intc   9>,
					      <&cpu1_intc   11>, < &cpu1_intc   9>,
					      <&cpu2_intc   11>, < &cpu2_intc   9>,
					      <&cpu3_intc   11>, < &cpu3_intc   9>,
					      <&cpu4_intc   11>, < &cpu4_intc   9>,
					      <&cpu5_intc   11>, < &cpu5_intc   9>,
					      <&cpu6_intc   11>, < &cpu6_intc   9>,
					      <&cpu7_intc   11>, < &cpu7_intc   9>,
					      <&cpu8_intc   11>, < &cpu8_intc   9>,
					      <&cpu9_intc   11>, < &cpu9_intc   9>,
					      <&cpu10_intc  11>, < &cpu10_intc  9>,
					      <&cpu11_intc  11>, < &cpu11_intc  9>,
					      <&cpu12_intc  11>, < &cpu12_intc  9>,
					      <&cpu13_intc  11>, < &cpu13_intc  9>,
					      <&cpu14_intc  11>, < &cpu14_intc  9>,
					      <&cpu15_intc  11>, < &cpu15_intc  9>,
					      <&cpu16_intc  11>, < &cpu16_intc  9>,
					      <&cpu17_intc  11>, < &cpu17_intc  9>,
					      <&cpu18_intc  11>, < &cpu18_intc  9>,
					      <&cpu19_intc  11>, < &cpu19_intc  9>,
					      <&cpu20_intc  11>, < &cpu20_intc  9>,
					      <&cpu21_intc  11>, < &cpu21_intc  9>,
					      <&cpu22_intc  11>, < &cpu22_intc  9>,
					      <&cpu23_intc  11>, < &cpu23_intc  9>,
					      <&cpu24_intc  11>, < &cpu24_intc  9>,
					      <&cpu25_intc  11>, < &cpu25_intc  9>,
					      <&cpu26_intc  11>, < &cpu26_intc  9>,
					      <&cpu27_intc  11>, < &cpu27_intc  9>,
					      <&cpu28_intc  11>, < &cpu28_intc  9>,
					      <&cpu29_intc  11>, < &cpu29_intc  9>,
					      <&cpu30_intc  11>, < &cpu30_intc  9>,
					      <&cpu31_intc  11>, < &cpu31_intc  9>,
					      <&cpu32_intc  11>, < &cpu32_intc  9>,
					      <&cpu33_intc  11>, < &cpu33_intc  9>,
					      <&cpu34_intc  11>, < &cpu34_intc  9>,
					      <&cpu35_intc  11>, < &cpu35_intc  9>,
					      <&cpu36_intc  11>, < &cpu36_intc  9>,
					      <&cpu37_intc  11>, < &cpu37_intc  9>,
					      <&cpu38_intc  11>, < &cpu38_intc  9>,
					      <&cpu39_intc  11>, < &cpu39_intc  9>,
					      <&cpu40_intc  11>, < &cpu40_intc  9>,
					      <&cpu41_intc  11>, < &cpu41_intc  9>,
					      <&cpu42_intc  11>, < &cpu42_intc  9>,
					      <&cpu43_intc  11>, < &cpu43_intc  9>,
					      <&cpu44_intc  11>, < &cpu44_intc  9>,
					      <&cpu45_intc  11>, < &cpu45_intc  9>,
					      <&cpu46_intc  11>, < &cpu46_intc  9>,
					      <&cpu47_intc  11>, < &cpu47_intc  9>,
					      <&cpu48_intc  11>, < &cpu48_intc  9>,
					      <&cpu49_intc  11>, < &cpu49_intc  9>,
					      <&cpu50_intc  11>, < &cpu50_intc  9>,
					      <&cpu51_intc  11>, < &cpu51_intc  9>,
					      <&cpu52_intc  11>, < &cpu52_intc  9>,
					      <&cpu53_intc  11>, < &cpu53_intc  9>,
					      <&cpu54_intc  11>, < &cpu54_intc  9>,
					      <&cpu55_intc  11>, < &cpu55_intc  9>,
					      <&cpu56_intc  11>, < &cpu56_intc  9>,
					      <&cpu57_intc  11>, < &cpu57_intc  9>,
					      <&cpu58_intc  11>, < &cpu58_intc  9>,
					      <&cpu59_intc  11>, < &cpu59_intc  9>,
					      <&cpu60_intc  11>, < &cpu60_intc  9>,
					      <&cpu61_intc  11>, < &cpu61_intc  9>,
					      <&cpu62_intc  11>, < &cpu62_intc  9>,
					      <&cpu63_intc  11>, < &cpu63_intc  9>;
		};
	};
};
